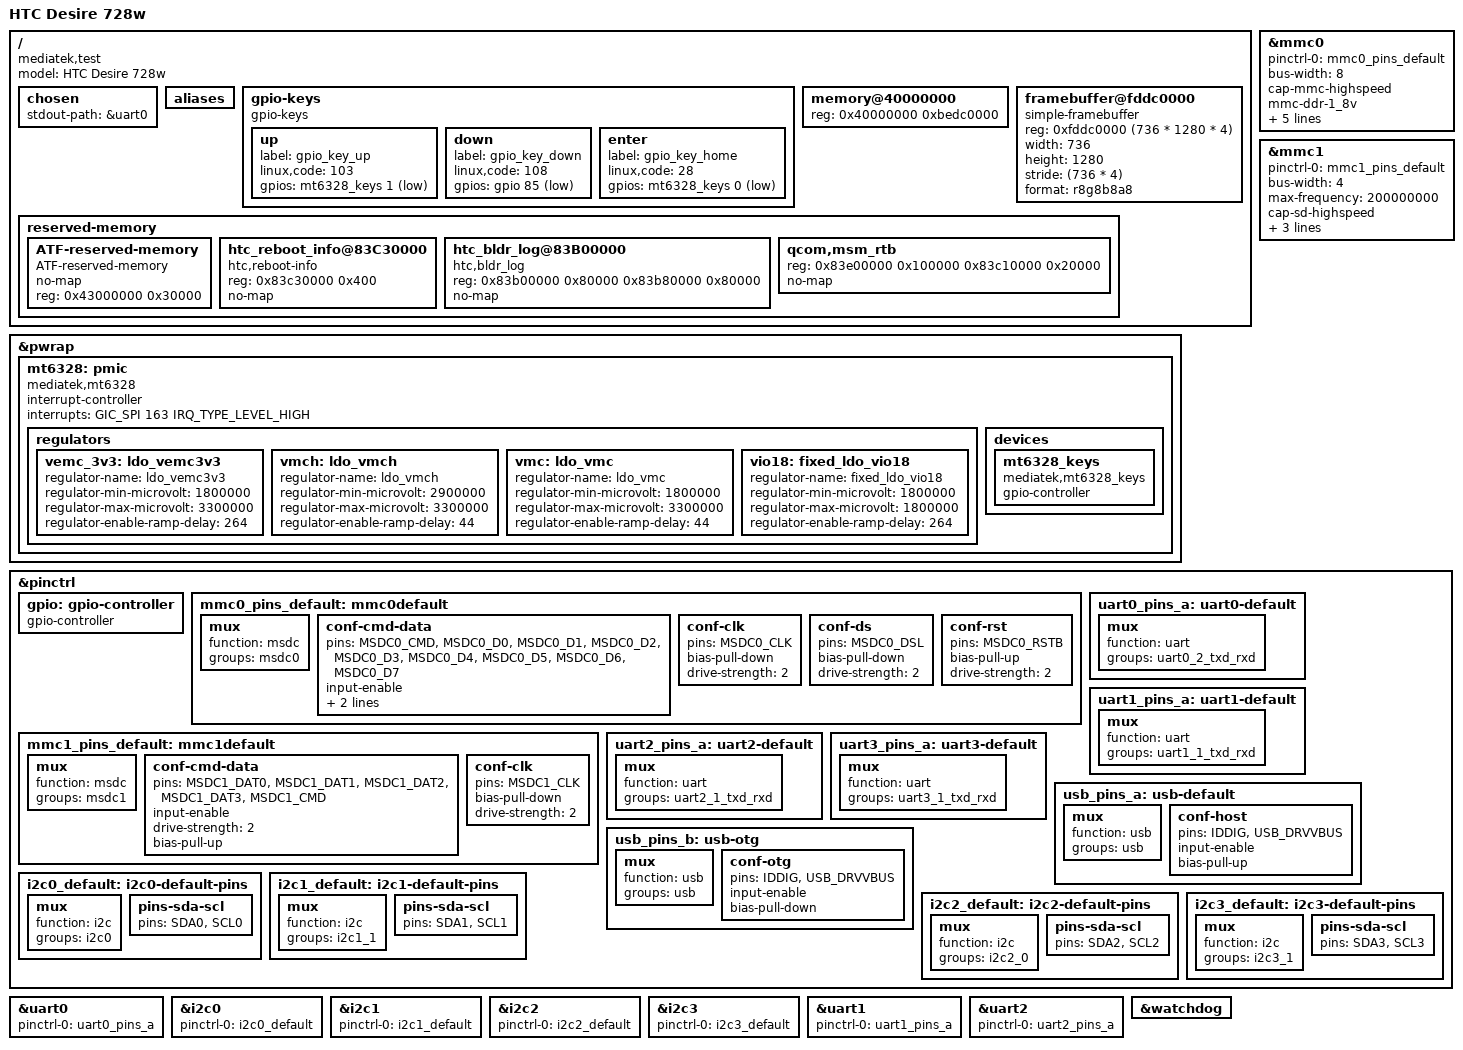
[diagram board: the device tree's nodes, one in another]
// SPDX-License-Identifier: GPL-2.0-or-later
/*
 * Copyright 2024 Denis Burkov <hitechshell@mail.ru>
 */

/dts-v1/;

#include "mt6735.dtsi"
#include "mt6735-u-boot.dtsi"


/ {
	#address-cells = <1>;
	#size-cells = <1>;

	model = "HTC Desire 728w";
	compatible = "mediatek,test", "mediatek,mt6735";

	chosen {
		stdout-path = &uart0;
	};
    
	aliases {
//        mmc1 = "/mmc@11230000";
//        mmc0 = "/mmc@11240000";
    };

	gpio-keys {
			compatible = "gpio-keys";

			up {
				label = "gpio_key_up";
				linux,code = <103>;
				gpios = <&mt6328_keys 1 GPIO_ACTIVE_LOW>;
			};

			down {
				label = "gpio_key_down";
				linux,code = <108>;
				gpios = <&gpio 85 GPIO_ACTIVE_LOW>;
			};
			
			enter {
				label = "gpio_key_home";
				linux,code = <28>;
				gpios = <&mt6328_keys 0 GPIO_ACTIVE_LOW>;
			};
	};

	memory@40000000 {
		device_type = "memory";
		reg = <0x40000000 0xbedc0000>;
	};
	
	framebuffer@fddc0000 {
		compatible = "simple-framebuffer";
		reg = <0xfddc0000 (736 * 1280 * 4)>;
		width = <736>;
		height = <1280>;
		stride = <(736 * 4)>;
		format = "r8g8b8a8";
	};

	reserved-memory {
		#address-cells = <1>;
		#size-cells = <1>;
		ranges;

		ATF-reserved-memory {
			compatible = "ATF-reserved-memory";
			no-map;
			reg = <0x43000000 0x30000>;
		};
		htc_reboot_info@83C30000 {
			reg = <0x83c30000 0x400>;
			no-map;
			compatible = "htc,reboot-info";
			reg-names = "htc_reboot_info_res";
		};

		htc_bldr_log@83B00000 {
			compatible = "htc,bldr_log";
			reg = <0x83b00000 0x80000 0x83b80000 0x80000>;
			no-map;
			reg-names = "bl_log\0bl_old_log";
		};

		qcom,msm_rtb {
			reg = <0x83e00000 0x100000 0x83c10000 0x20000>;
			no-map;
			reg-names = "msm_rtb_res\0htc_debug_rtb_res";
		};
	};
};

&pwrap {
    status = "okay";

    mt6328: pmic {
		compatible = "mediatek,mt6328";
		interrupt-controller;
//      interrupt-parent = <&pio>;
		interrupts = <GIC_SPI 163 IRQ_TYPE_LEVEL_HIGH>;
		#interrupt-cells = <2>;

		regulators {
			/*
			vcore1: buck_vcore1 {
						regulator-name = "buck_vcore1";
						regulator-always-on;
						regulator-min-microvolt = <600000>;
						regulator-max-microvolt = <1393750>;
                        bootph-all;
                };
                
			vproc: buck_vproc {
						regulator-name = "buck_vproc";
						regulator-always-on;
						regulator-min-microvolt = <600000>;
						regulator-max-microvolt = <1393750>;
                        bootph-all;
                };
                
			vlte: buck_vlte {
						regulator-name = "buck_vlte";
						regulator-always-on;
						regulator-min-microvolt = <600000>;
						regulator-max-microvolt = <1393750>;
                        bootph-all;
                };
                
			vsys22: buck_vsys22 {
						regulator-name = "buck_vsys22";
						regulator-min-microvolt = <1200000>;
						regulator-max-microvolt = <1993750>;
						regulator-ramp-delay = <6250>;
						regulator-enable-ramp-delay = <180>;
						regulator-always-on;
						regulator-boot-on;
                        bootph-all;
				};
                
			vpa: buck_vpa {
						regulator-name = "buck_vpa";
						regulator-min-microvolt = <500000>;
						regulator-max-microvolt = <3650000>;
						regulator-ramp-delay = <50000>;
						regulator-enable-ramp-delay = <180>;
                        bootph-all;
				};
                
			vsram: buck_vsram {
						regulator-name = "buck_vsram";
						regulator-min-microvolt = <700000>;
						regulator-max-microvolt = <1493750>;
						regulator-enable-ramp-delay = <220>;
						regulator-ramp-delay = <6250>;
						regulator-boot-on;
                        bootph-all;
				};
                
			vaux18: fixed_ldo_vaux18 {
						regulator-name = "fixed_ldo_vaux18";
						regulator-min-microvolt = <1800000>;
						regulator-max-microvolt = <1800000>;
						regulator-enable-ramp-delay = <264>;
						regulator-boot-on;
                        bootph-all;
				};

			vtcxo_0: fixed_ldo_vtcxo_0 {
						regulator-name = "fixed_ldo_vtcxo_0";
						regulator-min-microvolt = <2800000>;
						regulator-max-microvolt = <2800000>;
						regulator-enable-ramp-delay = <110>;
						regulator-boot-on;
                        bootph-all;
				};
                
			vtcxo_1: fixed_ldo_vtcxo_1 {
						regulator-name = "fixed_ldo_vtcxo_1";
						regulator-min-microvolt = <2800000>;
						regulator-max-microvolt = <2800000>;
						regulator-enable-ramp-delay = <110>;
                        bootph-all;
				};
                
			vaud28: fixed_ldo_vaud28 {
						regulator-name = "fixed_ldo_vaud28";
						regulator-min-microvolt = <2800000>;
						regulator-max-microvolt = <2800000>;
						regulator-enable-ramp-delay = <264>;
						regulator-boot-on;
                        bootph-all;
				};
                
			vcn28: fixed_ldo_vcn28 {
						regulator-name = "fixed_ldo_vcn28";
						regulator-min-microvolt = <2800000>;
						regulator-max-microvolt = <2800000>;
						regulator-enable-ramp-delay = <264>;
                        bootph-all;
				};
                
			vcama: ldo_vcama {
						regulator-name = "ldo_vcama";
						regulator-min-microvolt = <1500000>;
						regulator-max-microvolt = <2800000>;
						regulator-enable-ramp-delay = <264>;
                        bootph-all;
				};
                
			vcn33_bt: ldo_vcn33_bt {
						regulator-name = "ldo_vcn33_bt";
						regulator-min-microvolt = <3300000>;
						regulator-max-microvolt = <3600000>;
						regulator-enable-ramp-delay = <264>;
                        bootph-all;
				};
                
			vcn33_wifi: ldo_vcn33_wifi {
						regulator-name = "ldo_vcn33_wifi";
						regulator-min-microvolt = <3300000>;
						regulator-max-microvolt = <3600000>;
						regulator-enable-ramp-delay = <264>;
                        bootph-all;
				};
                
			vusb33: fixed_ldo_vusb33 {
						regulator-name = "fixed_ldo_vusb33";
						regulator-min-microvolt = <3300000>;
						regulator-max-microvolt = <3300000>;
						regulator-enable-ramp-delay = <264>;
						regulator-boot-on;
                        bootph-all;
				};
                
			vefuse: ldo_vefuse {
						regulator-name = "ldo_vefuse";
						regulator-min-microvolt = <1800000>;
						regulator-max-microvolt = <2200000>;
						regulator-enable-ramp-delay = <264>;
                        bootph-all;
				};
                
			sim1: ldo_vsim1 {
						regulator-name = "ldo_vsim1";
						regulator-min-microvolt = <1700000>;
						regulator-max-microvolt = <2100000>;
						regulator-enable-ramp-delay = <264>;
                        bootph-all;
				};
                
			sim2: ldo_vsim2 {
						regulator-name = "ldo_vsim2";
						regulator-min-microvolt = <1700000>;
						regulator-max-microvolt = <2100000>;
						regulator-enable-ramp-delay = <264>;
                        bootph-all;
				};
            */    
			vemc_3v3: ldo_vemc3v3 {
						regulator-name = "ldo_vemc3v3";
						regulator-min-microvolt = <1800000>;
						regulator-max-microvolt = <3300000>;
						regulator-enable-ramp-delay = <264>;
                        bootph-all;
				};
			vmch: ldo_vmch {
						regulator-name = "ldo_vmch";
						regulator-min-microvolt = <2900000>;
						regulator-max-microvolt = <3300000>;
						regulator-enable-ramp-delay = <44>;
                        bootph-all;
				};
                /*
			vtref: fixed_ldo_vtref {
						regulator-name = "fixed_ldo_vtref";
						regulator-min-microvolt = <1800000>;
						regulator-max-microvolt = <1800000>;
						regulator-enable-ramp-delay = <240>;
                        bootph-all;
				};
            */    
			vmc: ldo_vmc {
						regulator-name = "ldo_vmc";
						regulator-min-microvolt = <1800000>;
						regulator-max-microvolt = <3300000>;
						regulator-enable-ramp-delay = <44>;
                        bootph-all;
				};
              /*  
			vcamaf: ldo_vcamaf {
						regulator-name = "ldo_vcamaf";
						regulator-min-microvolt = <1200000>;
						regulator-max-microvolt = <3300000>;
						regulator-enable-ramp-delay = <264>;
                        bootph-all;
				};
                
			vio28: fixed_ldo_vio28 {
						regulator-name = "fixed_ldo_vio28";
						regulator-min-microvolt = <2800000>;
						regulator-max-microvolt = <2800000>;
						regulator-enable-ramp-delay = <264>;
						regulator-boot-on;
                        bootph-all;
                };

			vrtc: fixed_ldo_vrtc {
						regulator-name = "fixed_ldo_vrtc";
						regulator-min-microvolt = <2800000>;
						regulator-max-microvolt = <2800000>;
						regulator-enable-ramp-delay = <264>;
						regulator-boot-on;
                        bootph-all;
                };
                
			vgp1: ldo_vgp1 {
						regulator-name = "ldo_vgp1";
						regulator-min-microvolt = <1200000>;
						regulator-max-microvolt = <3300000>;
						regulator-enable-ramp-delay = <264>;
                        bootph-all;
				};
                
			vibr: ldo_vibr {
						regulator-name = "ldo_vibr";
						regulator-min-microvolt = <1200000>;
						regulator-max-microvolt = <3300000>;
						regulator-enable-ramp-delay = <44>;
                        bootph-all;
				};
                
			vcamd: ldo_vcamd {
						regulator-name = "ldo_vcamd";
						regulator-min-microvolt = <900000>;
						regulator-max-microvolt = <1500000>;
						regulator-enable-ramp-delay = <264>;
                        bootph-all;
				};
                
			vrf18_0: fixed_ldo_vrf18_0 {
						regulator-name = "fixed_ldo_vrf18_0";
						regulator-min-microvolt = <1825000>;
						regulator-max-microvolt = <1825000>;
						regulator-enable-ramp-delay = <220>;
                        bootph-all;
				};
                
			vrf18_1: fixed_ldo_vrf18_1 {
						regulator-name = "fixed_ldo_vrf18_1";
						regulator-min-microvolt = <1200000>;
						regulator-max-microvolt = <1825000>;
						regulator-enable-ramp-delay = <220>;
                        bootph-all;
				};
            */    
			vio18: fixed_ldo_vio18 {
						regulator-name = "fixed_ldo_vio18";
						regulator-min-microvolt = <1800000>;
						regulator-max-microvolt = <1800000>;
						regulator-enable-ramp-delay = <264>;
                        bootph-all;
				};
              /*  
			vcn18: fixed_ldo_vcn18 {
						regulator-name = "fixed_ldo_vcn18";
						regulator-min-microvolt = <1800000>;
						regulator-max-microvolt = <1800000>;
						regulator-enable-ramp-delay = <44>;
                        bootph-all;
				};
                
			vcamio: ldo_vcamio {
						regulator-name = "ldo_vcamio";
						regulator-min-microvolt = <1200000>;
						regulator-max-microvolt = <1800000>;
						regulator-enable-ramp-delay = <220>;
                        bootph-all;
				};
                
			vm: ldo_vm {
						regulator-name = "ldo_vm";
						regulator-min-microvolt = <1240000>;
						regulator-max-microvolt = <1540000>;
						regulator-enable-ramp-delay = <264>;
						regulator-boot-on;
                        bootph-all;
                };
				*/
            };
            
		devices {
        
            mt6328_keys: mt6328_keys {
				compatible = "mediatek,mt6328_keys";
				#gpio-cells = <2>;
				gpio-controller;
                bootph-all;
            };
        };
    };
};

&mmc0 {
	pinctrl-names = "default";
	pinctrl-0 = <&mmc0_pins_default>;
	bus-width = <8>;
	cap-mmc-highspeed;
//	mmc-hs400-1_8v;
	mmc-ddr-1_8v;
	cap-mmc-hw-reset;
	max-frequency = <200000000>;
	vmmc-supply = <&vemc_3v3>;
	vqmmc-supply = <&vio18>;
	non-removable;
	status = "okay";
};

&mmc1 {
	pinctrl-names = "default";
	pinctrl-0 = <&mmc1_pins_default>;
	status = "okay";
	bus-width = <4>;
	max-frequency = <200000000>;
	cap-sd-highspeed;
	sd-uhs-sdr104;
	vmmc-supply = <&vmch>;
	vqmmc-supply = <&vmc>;
};

&pinctrl {

    gpio: gpio-controller {
            gpio-controller;
            #gpio-cells = <2>;
            bootph-all;
        };    
	mmc0_pins_default: mmc0default {
		mux {
			function = "msdc";
			groups =  "msdc0";
            bootph-all;
		};

		conf-cmd-data {
			pins = "MSDC0_CMD", "MSDC0_D0", "MSDC0_D1",
			       "MSDC0_D2", "MSDC0_D3", "MSDC0_D4",
			       "MSDC0_D5", "MSDC0_D6", "MSDC0_D7";
			input-enable;
            drive-strength = <2>;
			bias-pull-up;
            bootph-all;
		};

		conf-clk {
			pins = "MSDC0_CLK";
			bias-pull-down;
            drive-strength = <2>;
            bootph-all;
		};

		conf-ds {
			pins = "MSDC0_DSL";
			bias-pull-down;
            drive-strength = <2>;
            bootph-all;
		};

		conf-rst {
			pins = "MSDC0_RSTB";
			bias-pull-up;
            drive-strength = <2>;
            bootph-all;
		};
	};

	mmc1_pins_default: mmc1default {
		mux {
			function = "msdc";
			groups =  "msdc1";
            bootph-all;
		};

		conf-cmd-data {
			pins = "MSDC1_DAT0", "MSDC1_DAT1", "MSDC1_DAT2",
			       "MSDC1_DAT3", "MSDC1_CMD";
			input-enable;
            drive-strength = <2>;
			bias-pull-up;
            bootph-all;
		};

		conf-clk {
			pins = "MSDC1_CLK";
			bias-pull-down;
            drive-strength = <2>;
            bootph-all;
		};

	};
	uart0_pins_a: uart0-default {
		mux {
			function = "uart";
			groups =  "uart0_2_txd_rxd";
		};
	};

	uart1_pins_a: uart1-default {
		mux {
			function = "uart";
			groups =  "uart1_1_txd_rxd";
		};
	};

	uart2_pins_a: uart2-default {
		mux {
			function = "uart";
			groups =  "uart2_1_txd_rxd";
		};
	};

	uart3_pins_a: uart3-default {
		mux {
			function = "uart";
			groups =  "uart3_1_txd_rxd";
		};
	};

	usb_pins_a: usb-default {
		mux {
			function = "usb";
			groups = "usb";
		};

		conf-host {
			pins = "IDDIG", "USB_DRVVBUS";
			input-enable;
			bias-pull-up;
		};
	};

	usb_pins_b: usb-otg {
		mux {
			function = "usb";
			groups = "usb";
		};

		conf-otg {
			pins = "IDDIG", "USB_DRVVBUS";
			input-enable;
			bias-pull-down;
		};
	};
    
    i2c0_default: i2c0-default-pins {
        mux {
            function = "i2c";
            groups = "i2c0";
        };
        
        pins-sda-scl {
            pins = "SDA0", "SCL0";
        };
    };

    i2c1_default: i2c1-default-pins {
        mux {
            function = "i2c";
            groups = "i2c1_1";
        };
        
        pins-sda-scl {
            pins = "SDA1", "SCL1";
        };
    };

    i2c2_default: i2c2-default-pins {
        mux {
            function = "i2c";
            groups = "i2c2_0";
        };
        
        pins-sda-scl {
            pins = "SDA2", "SCL2";
        };
    };

    i2c3_default: i2c3-default-pins {
        mux {
            function = "i2c";
            groups = "i2c3_1";
        };
        
        pins-sda-scl {
            pins = "SDA3", "SCL3";
        };
    };

};

&uart0 {
	pinctrl-names = "default";
	pinctrl-0 = <&uart0_pins_a>;
	status = "okay";
};

&i2c0 {
    pinctrl-names = "default";
    pinctrl-0 = <&i2c0_default>;
    status = "okay";
};

&i2c1 {
    pinctrl-names = "default";
    pinctrl-0 = <&i2c1_default>;
    status = "okay";
};

&i2c2 {
    pinctrl-names = "default";
    pinctrl-0 = <&i2c2_default>;
    status = "okay";
};

&i2c3 {
    pinctrl-names = "default";
    pinctrl-0 = <&i2c3_default>;
    status = "okay";
};

&uart1 {
	pinctrl-names = "default";
	pinctrl-0 = <&uart1_pins_a>;
	status = "okay";
};

&uart2 {
	pinctrl-names = "default";
	pinctrl-0 = <&uart2_pins_a>;
	status = "okay";
};

&watchdog {
	status = "okay";
};
/*
&usb2 {
	status = "okay";
	vusb33-supply = <&vusb33>;
	vcore-supply = <&vcore1>;
	pinctrl-names = "peripheral", "host";
	pinctrl-0 = <&usb_pins_b>;
	pinctrl-1 = <&usb_pins_a>;
	dr_mode = "peripheral";

	usb_con_b: connector {
		compatible = "usb-b-connector";
		label = "USB-B";
	};
};

&usb2phy {
	status = "okay";
	vusb33-supply = <&vusb33>;
};

&usb2port0 {
	status = "okay";
 	vcc-supply = <&vusb33>;
};
*/
